# HC32F334F8UI register map
File version: 1.0
CPU: CM4 r0p1, little endian, MPU, FPU, 4 interrupt priority bits
Registers are 32-bit, read-write, reset 0x0 unless marked. A register's access mark holds for its fields unless they carry their own. Offsets are from the block's base; [hi:lo] are bit positions; {n}, {i} and the like mark numbered series; 'fields as' and 'values as' point back to an identical list.

## HRPWM1
Base 0x4003C000
0x00 CNTER
  [21:0] CNT
0x04 UPDAR
  [21:0] UPDA
0x40 HRPERAR reset 0x3FFFC0
  [21:0] HRPERA
0x44 HRPERBR reset 0x3FFFC0
  [21:0] HRPERB
0x80 HRGCMAR reset 0x3FFFC0
  [21:0] HRGCMA
0x84 HRGCMBR reset 0x3FFFC0
  [21:0] HRGCMB
0x88 HRGCMCR reset 0x3FFFC0
  [21:0] HRGCMC
0x8C HRGCMDR reset 0x3FFFC0
  [21:0] HRGCMD
0x90 HRGCMER reset 0x3FFFC0
  [21:0] HRGCME
0x94 HRGCMFR reset 0x3FFFC0
  [21:0] HRGCMF
0x98 HRGCMGR reset 0x3FFFC0
  [21:0] HRGCMG
0x9C HRGCMHR reset 0x3FFFC0
  [21:0] HRGCMH
0xC0 SCMAR reset 0x3FFFC0
  [21:0] SCMA
0xC4 SCMBR reset 0x3FFFC0
  [21:0] SCMB
0xC8 SCMCR reset 0x3FFFC0
  [21:0] SCMC
0xCC SCMDR reset 0x3FFFC0
  [21:0] SCMD
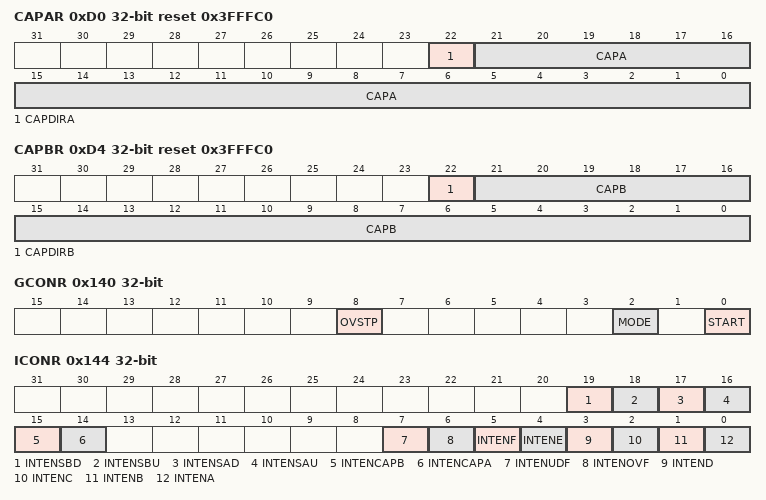
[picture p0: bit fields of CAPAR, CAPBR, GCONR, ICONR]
0xD0 CAPAR reset 0x3FFFC0
  [22] CAPDIRA ro, [21:0] CAPA
0xD4 CAPBR reset 0x3FFFC0
  [22] CAPDIRB ro, [21:0] CAPB
0x100 HRDTUAR reset 0x3FFFC0
  [21:0] HRDTUA
0x104 HRDTDAR reset 0x3FFFC0
  [21:0] HRDTDA
0x108 HRDTUBR reset 0x3FFFC0
  [21:0] HRDTUB
0x10C HRDTDBR reset 0x3FFFC0
  [21:0] HRDTDB
0x140 GCONR
  [8] OVSTP, [2] MODE, [0] START
0x144 ICONR
  [19] INTENSBD, [18] INTENSBU, [17] INTENSAD, [16] INTENSAU, [15] INTENCAPB, [14] INTENCAPA, [7] INTENUDF, [6] INTENOVF, [5] INTENF, [4] INTENE, [3] INTEND, [2] INTENC, [1] INTENB, [0] INTENA
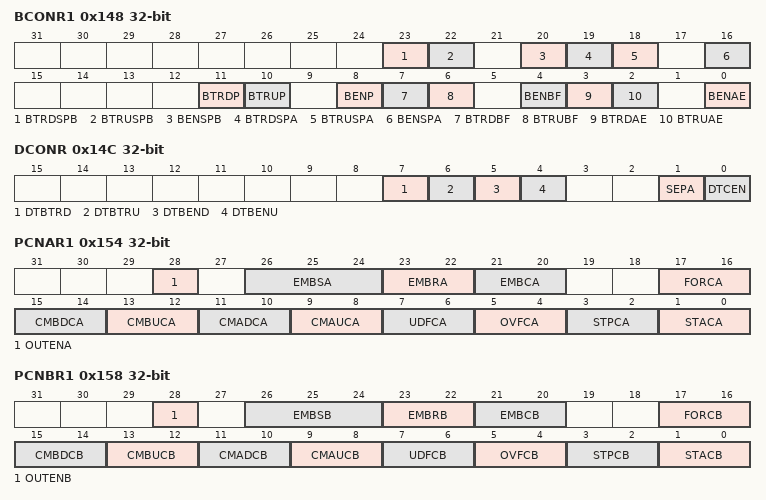
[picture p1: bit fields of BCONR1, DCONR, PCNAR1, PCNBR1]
0x148 BCONR1
  [23] BTRDSPB, [22] BTRUSPB, [20] BENSPB, [19] BTRDSPA, [18] BTRUSPA, [16] BENSPA, [11] BTRDP, [10] BTRUP, [8] BENP, [7] BTRDBF, [6] BTRUBF, [4] BENBF, [3] BTRDAE, [2] BTRUAE, [0] BENAE
0x14C DCONR
  [7] DTBTRD, [6] DTBTRU, [5] DTBEND, [4] DTBENU, [1] SEPA, [0] DTCEN
0x154 PCNAR1
  [28] OUTENA, [26:24] EMBSA, [23:22] EMBRA, [21:20] EMBCA, [17:16] FORCA, [15:14] CMBDCA, [13:12] CMBUCA, [11:10] CMADCA, [9:8] CMAUCA, [7:6] UDFCA, [5:4] OVFCA, [3:2] STPCA, [1:0] STACA
0x158 PCNBR1
  [28] OUTENB, [26:24] EMBSB, [23:22] EMBRB, [21:20] EMBCB, [17:16] FORCB, [15:14] CMBDCB, [13:12] CMBUCB, [11:10] CMADCB, [9:8] CMAUCB, [7:6] UDFCB, [5:4] OVFCB, [3:2] STPCB, [1:0] STACB
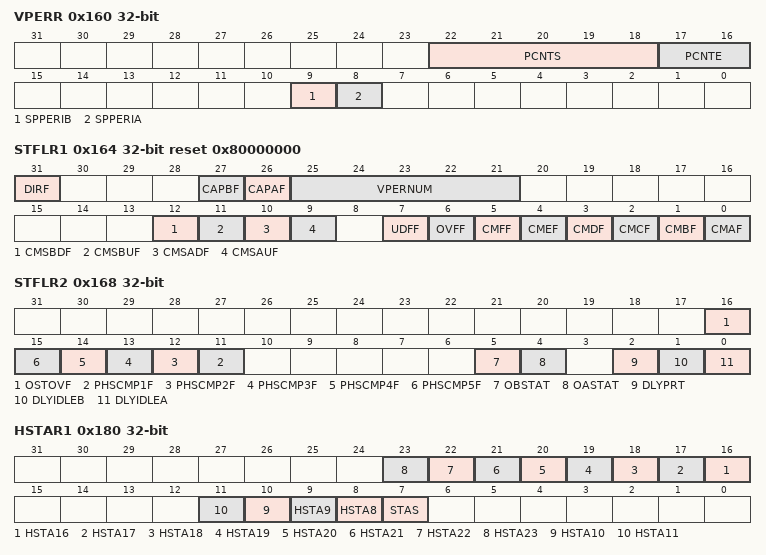
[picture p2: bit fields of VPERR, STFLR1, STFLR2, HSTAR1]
0x160 VPERR
  [22:18] PCNTS, [17:16] PCNTE, [9] SPPERIB, [8] SPPERIA
0x164 STFLR1 reset 0x80000000
  [31] DIRF ro, [27] CAPBF, [26] CAPAF, [25:21] VPERNUM ro, [12] CMSBDF, [11] CMSBUF, [10] CMSADF, [9] CMSAUF, [7] UDFF, [6] OVFF, [5] CMFF, [4] CMEF, [3] CMDF, [2] CMCF, [1] CMBF, [0] CMAF
0x168 STFLR2
  [16] OSTOVF, [n+10] PHSCMP{n}F (n=1..5), [5] OBSTAT, [4] OASTAT, [2] DLYPRT, [1] DLYIDLEB, [0] DLYIDLEA
0x180 HSTAR1
  [n] HSTA{n} (n=16..23), [n] HSTA{n} (n=8..11), [7] STAS
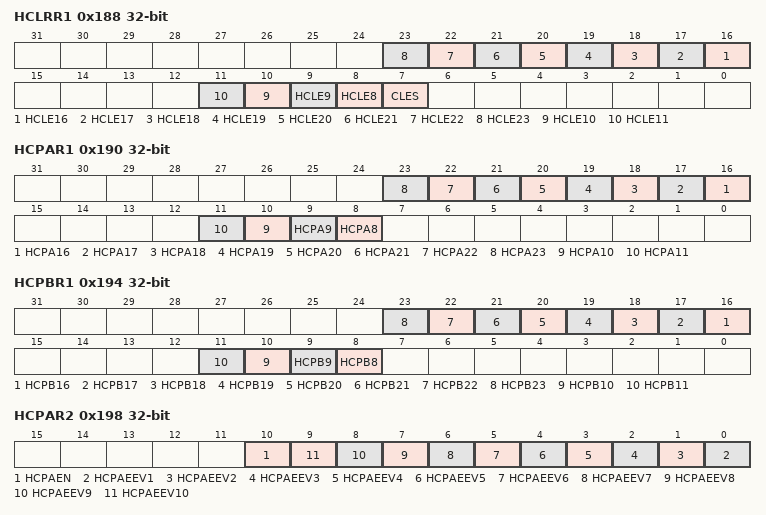
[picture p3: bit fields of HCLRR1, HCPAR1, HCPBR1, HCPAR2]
0x188 HCLRR1
  [n] HCLE{n} (n=16..23), [n] HCLE{n} (n=8..11), [7] CLES
0x190 HCPAR1
  [n] HCPA{n} (n=16..23), [n] HCPA{n} (n=8..11)
0x194 HCPBR1
  [n] HCPB{n} (n=16..23), [n] HCPB{n} (n=8..11)
0x198 HCPAR2
  [10] HCPAEN, [n-1] HCPAEEV{n} (n=1..10)
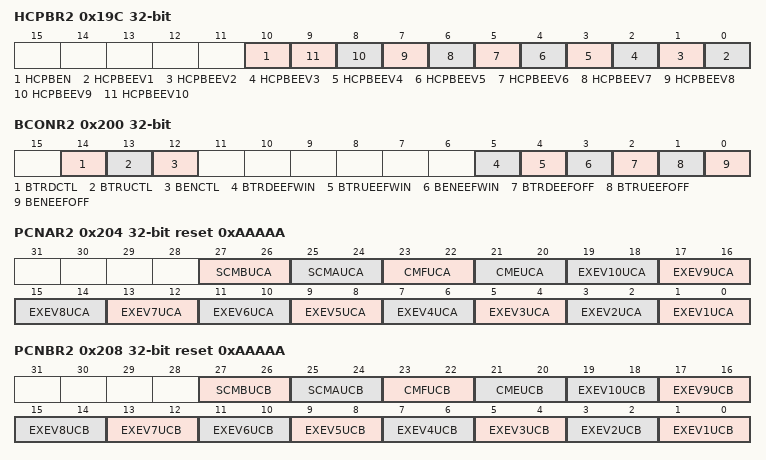
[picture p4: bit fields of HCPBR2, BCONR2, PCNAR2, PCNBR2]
0x19C HCPBR2
  [10] HCPBEN, [n-1] HCPBEEV{n} (n=1..10)
0x200 BCONR2
  [14] BTRDCTL, [13] BTRUCTL, [12] BENCTL, [5] BTRDEEFWIN, [4] BTRUEEFWIN, [3] BENEEFWIN, [2] BTRDEEFOFF, [1] BTRUEEFOFF, [0] BENEEFOFF
0x204 PCNAR2 reset 0xAAAAA
  [27:26] SCMBUCA, [25:24] SCMAUCA, [23:22] CMFUCA, [21:20] CMEUCA, [2n-1:2n-2] EXEV{n}UCA (n=1..10)
0x208 PCNBR2 reset 0xAAAAA
  [27:26] SCMBUCB, [25:24] SCMAUCB, [23:22] CMFUCB, [21:20] CMEUCB, [2n-1:2n-2] EXEV{n}UCB (n=1..10)
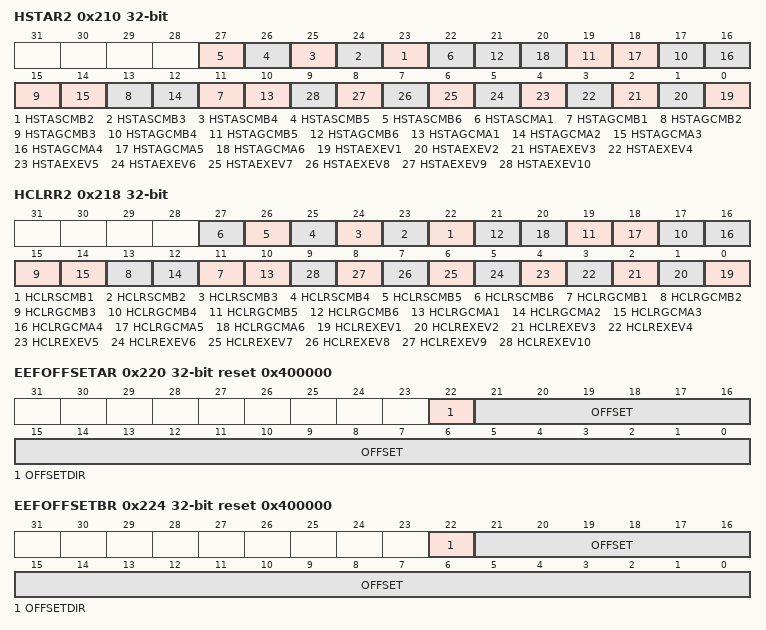
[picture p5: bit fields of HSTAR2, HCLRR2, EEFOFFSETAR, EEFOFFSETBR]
0x210 HSTAR2
  [n+21] HSTASCMB{n} (n=2..6), [22] HSTASCMA1, [2n+9] HSTAGCMB{n} (n=1..6), [2n+8] HSTAGCMA{n} (n=1..6), [n-1] HSTAEXEV{n} (n=1..10)
0x218 HCLRR2
  [n+21] HCLRSCMB{n} (n=1..6), [2n+9] HCLRGCMB{n} (n=1..6), [2n+8] HCLRGCMA{n} (n=1..6), [n-1] HCLREXEV{n} (n=1..10)
0x220 EEFOFFSETAR reset 0x400000
  [22] OFFSETDIR, [21:0] OFFSET
0x224 EEFOFFSETBR reset 0x400000
  [22] OFFSETDIR, [21:0] OFFSET
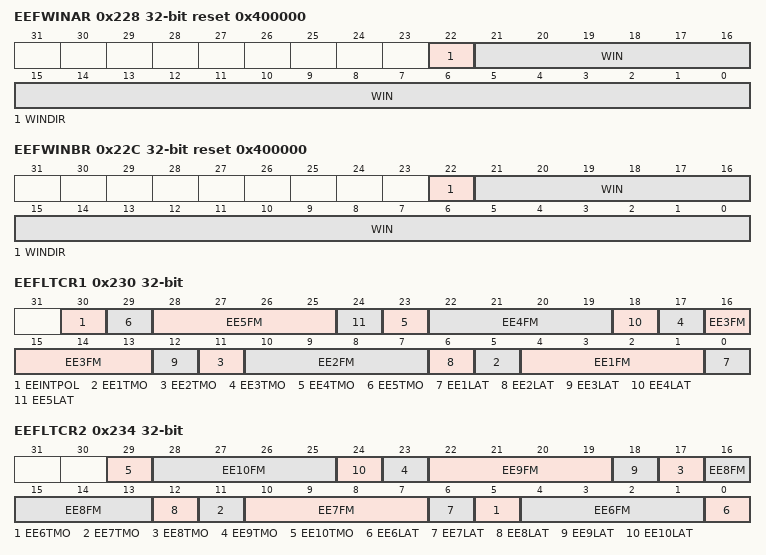
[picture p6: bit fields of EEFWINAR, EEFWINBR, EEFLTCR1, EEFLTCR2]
0x228 EEFWINAR reset 0x400000
  [22] WINDIR, [21:0] WIN
0x22C EEFWINBR reset 0x400000
  [22] WINDIR, [21:0] WIN
0x230 EEFLTCR1
  [30] EEINTPOL, [6n-1] EE{n}TMO (n=1..5), [6n-2:6n-5] EE{n}FM (n=1..5), [6n-6] EE{n}LAT (n=1..5)
0x234 EEFLTCR2
  [6n-31] EE{n}TMO (n=6..10), [6n-32:6n-35] EE{n}FM (n=6..10), [6n-36] EE{n}LAT (n=6..10)
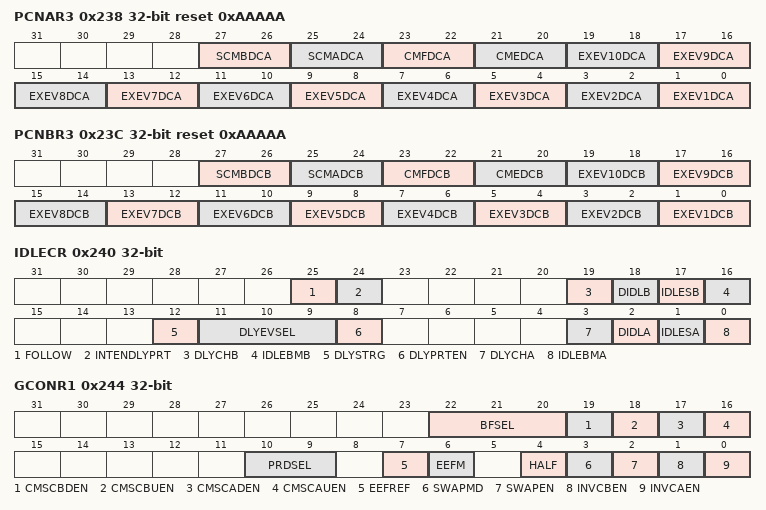
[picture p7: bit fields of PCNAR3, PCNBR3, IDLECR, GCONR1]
0x238 PCNAR3 reset 0xAAAAA
  [27:26] SCMBDCA, [25:24] SCMADCA, [23:22] CMFDCA, [21:20] CMEDCA, [2n-1:2n-2] EXEV{n}DCA (n=1..10)
0x23C PCNBR3 reset 0xAAAAA
  [27:26] SCMBDCB, [25:24] SCMADCB, [23:22] CMFDCB, [21:20] CMEDCB, [2n-1:2n-2] EXEV{n}DCB (n=1..10)
0x240 IDLECR
  [25] FOLLOW, [24] INTENDLYPRT, [19] DLYCHB, [18] DIDLB, [17] IDLESB, [16] IDLEBMB, [12] DLYSTRG, [11:9] DLYEVSEL, [8] DLYPRTEN, [3] DLYCHA, [2] DIDLA, [1] IDLESA, [0] IDLEBMA
0x244 GCONR1
  [22:20] BFSEL, [19] CMSCBDEN, [18] CMSCBUEN, [17] CMSCADEN, [16] CMSCAUEN, [10:9] PRDSEL, [7] EEFREF, [6] EEFM, [4] HALF, [3] SWAPMD, [2] SWAPEN, [1] INVCBEN, [0] INVCAEN
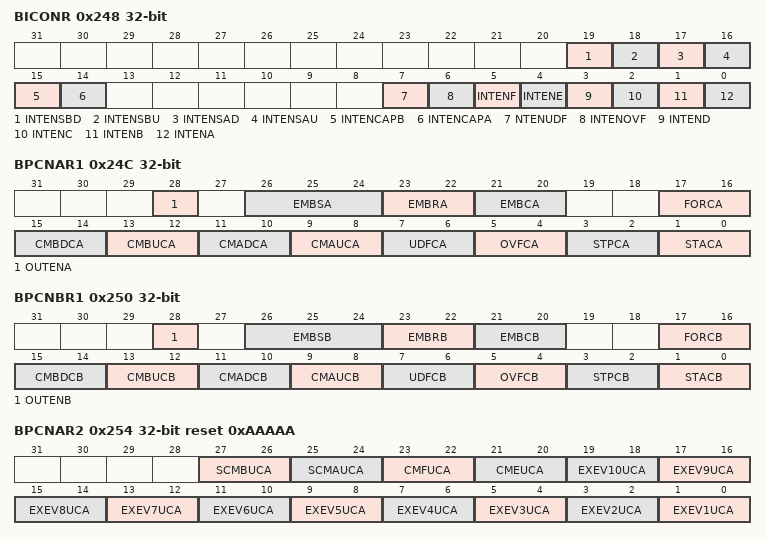
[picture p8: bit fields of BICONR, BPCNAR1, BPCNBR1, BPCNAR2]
0x248 BICONR
  [19] INTENSBD, [18] INTENSBU, [17] INTENSAD, [16] INTENSAU, [15] INTENCAPB, [14] INTENCAPA, [7] NTENUDF, [6] INTENOVF, [5] INTENF, [4] INTENE, [3] INTEND, [2] INTENC, [1] INTENB, [0] INTENA
0x24C BPCNAR1
  fields as PCNAR1
0x250 BPCNBR1
  fields as PCNBR1
0x254 BPCNAR2 reset 0xAAAAA
  fields as PCNAR2
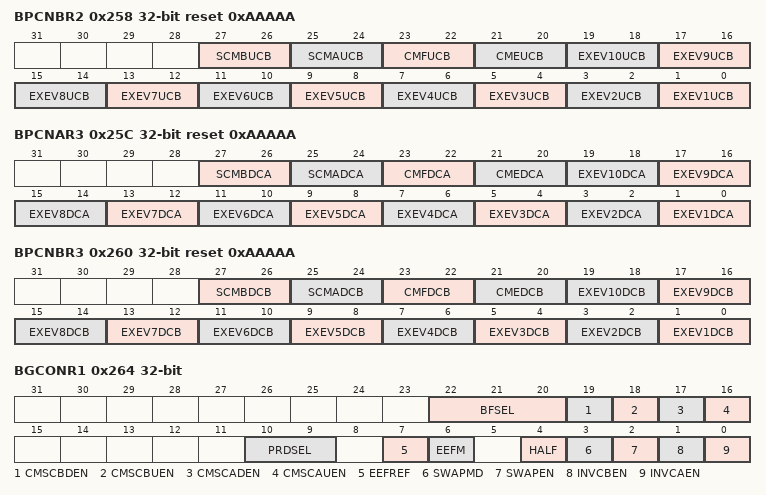
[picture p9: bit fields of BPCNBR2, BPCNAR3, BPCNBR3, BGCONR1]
0x258 BPCNBR2 reset 0xAAAAA
  fields as PCNBR2
0x25C BPCNAR3 reset 0xAAAAA
  fields as PCNAR3
0x260 BPCNBR3 reset 0xAAAAA
  fields as PCNBR3
0x264 BGCONR1
  fields as GCONR1
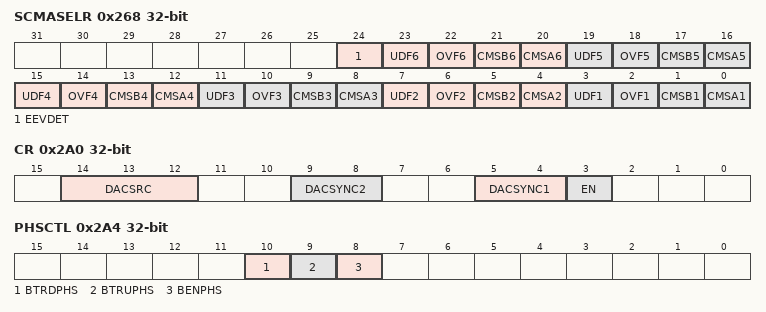
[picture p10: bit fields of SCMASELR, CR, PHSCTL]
0x268 SCMASELR
  [24] EEVDET, [4n-1] UDF{n} (n=1..6), [4n-2] OVF{n} (n=1..6), [4n-3] CMSB{n} (n=1..6), [4n-4] CMSA{n} (n=1..6)
0x2A0 CR
  [14:12] DACSRC, [9:8] DACSYNC2, [5:4] DACSYNC1, [3] EN
0x2A4 PHSCTL
  [10] BTRDPHS, [9] BTRUPHS, [8] BENPHS
{0x2AC+8i} PHSCMP{i}A reset 0x7FFFC0 (i=1..5)
  [22:0] PHSCMP{i}A
{0x2B0+8i} PHSCMP{i}B reset 0x7FFFC0 (i=1..5)
  [22:0] PHSCMP{i}B

## HRPWM2 — desc HRPWM
Base 0x4003C400
Same registers: HRPWM3 0x4003C800, HRPWM4 0x4003CC00, HRPWM5 0x4003D000, HRPWM6 0x4003D400
Registers as HRPWM1, without PHSCMP{n}A (n=1..5), PHSCMP{n}B (n=1..5); these are added or differ:
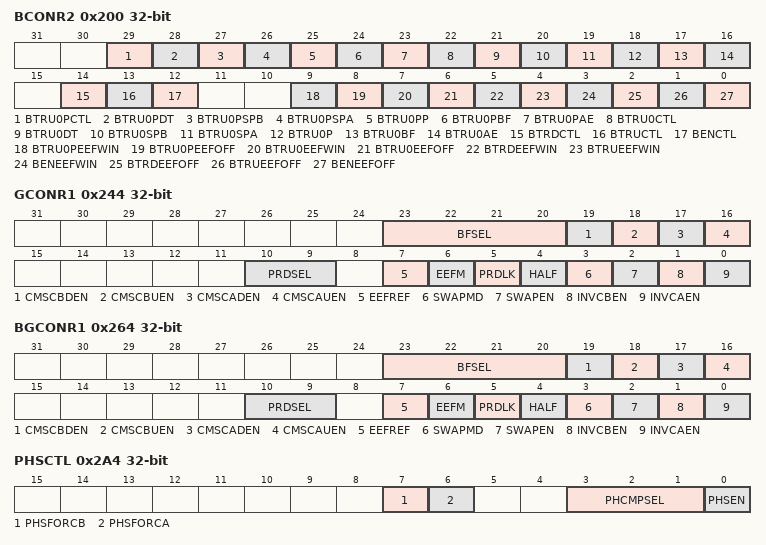
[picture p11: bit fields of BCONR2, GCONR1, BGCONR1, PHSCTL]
0x200 BCONR2
  [29] BTRU0PCTL, [28] BTRU0PDT, [27] BTRU0PSPB, [26] BTRU0PSPA, [25] BTRU0PP, [24] BTRU0PBF, [23] BTRU0PAE, [22] BTRU0CTL, [21] BTRU0DT, [20] BTRU0SPB, [19] BTRU0SPA, [18] BTRU0P, [17] BTRU0BF, [16] BTRU0AE, [14] BTRDCTL, [13] BTRUCTL, [12] BENCTL, [9] BTRU0PEEFWIN, [8] BTRU0PEEFOFF, [7] BTRU0EEFWIN, [6] BTRU0EEFOFF, [5] BTRDEEFWIN, [4] BTRUEEFWIN, [3] BENEEFWIN, [2] BTRDEEFOFF, [1] BTRUEEFOFF, [0] BENEEFOFF
0x244 GCONR1
  [23:20] BFSEL, [19] CMSCBDEN, [18] CMSCBUEN, [17] CMSCADEN, [16] CMSCAUEN, [10:9] PRDSEL, [7] EEFREF, [6] EEFM, [5] PRDLK, [4] HALF, [3] SWAPMD, [2] SWAPEN, [1] INVCBEN, [0] INVCAEN
0x264 BGCONR1
  fields as GCONR1
0x2A4 PHSCTL
  [7] PHSFORCB, [6] PHSFORCA, [3:1] PHCMPSEL, [0] PHSEN
